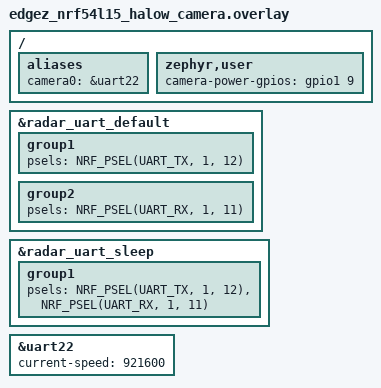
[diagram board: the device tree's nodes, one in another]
#include "edgez_nrf54l15_halow_light_radar.overlay"

/* VC0706 uses the shared serial connector and power enable in this profile. */
/ {
	aliases {
		camera0 = &uart22;
	};
	zephyr,user {
		camera-power-gpios = <&gpio1 9 GPIO_ACTIVE_HIGH>;
	};
};

&radar_uart_default {
	group1 {
		psels = <NRF_PSEL(UART_TX, 1, 12)>;
	};
	group2 {
		psels = <NRF_PSEL(UART_RX, 1, 11)>;
	};
};

&radar_uart_sleep {
	group1 {
		psels = <NRF_PSEL(UART_TX, 1, 12)>,
			<NRF_PSEL(UART_RX, 1, 11)>;
	};
};

&uart22 {
	current-speed = <921600>;
};
